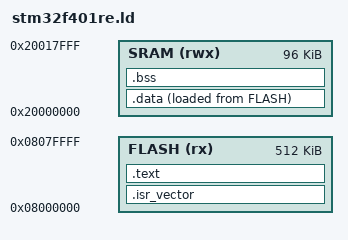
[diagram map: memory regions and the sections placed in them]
/* STM32F401RE: 512KB Flash @ 0x08000000, 96KB SRAM @ 0x20000000 */
MEMORY
{
  FLASH (rx)  : ORIGIN = 0x08000000, LENGTH = 512K
  SRAM  (rwx) : ORIGIN = 0x20000000, LENGTH = 96K
}

ENTRY(Reset_Handler)

SECTIONS
{
  .isr_vector :
  {
    KEEP(*(.isr_vector))
  } > FLASH

  .text :
  {
    *(.text*)
    *(.rodata*)
    _etext = .;
  } > FLASH

  .data :
  {
    _sdata = .;
    *(.data*)
    _edata = .;
  } > SRAM AT > FLASH

  _sidata = LOADADDR(.data);

  .bss :
  {
    _sbss = .;
    *(.bss*)
    *(COMMON)
    _ebss = .;
  } > SRAM

  _estack = ORIGIN(SRAM) + LENGTH(SRAM);
}
